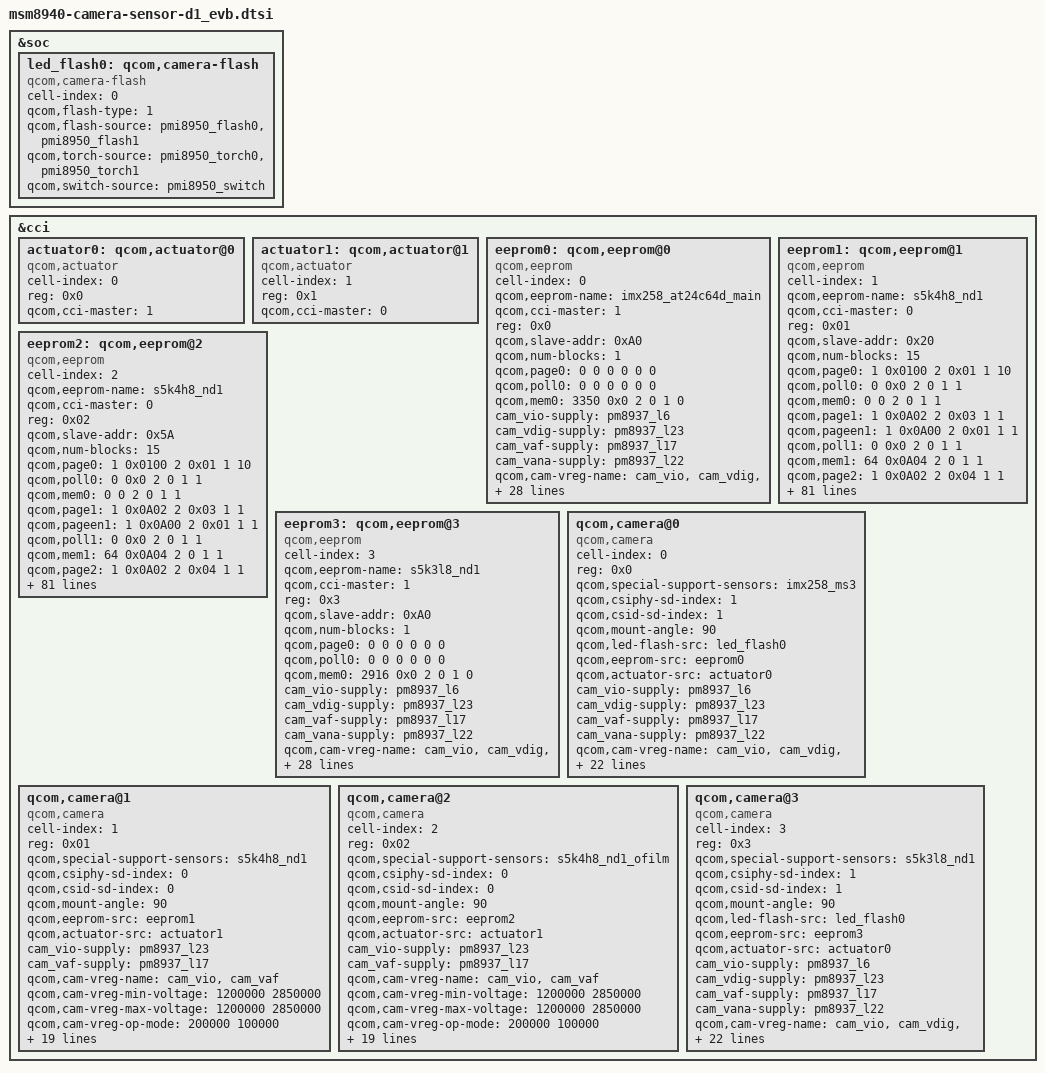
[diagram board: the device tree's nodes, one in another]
/*
 * Copyright (c) 2015-2016, The Linux Foundation. All rights reserved.
 *
 * This program is free software; you can redistribute it and/or modify
 * it under the terms of the GNU General Public License version 2 and
 * only version 2 as published by the Free Software Foundation.
 *
 * This program is distributed in the hope that it will be useful,
 * but WITHOUT ANY WARRANTY; without even the implied warranty of
 * MERCHANTABILITY or FITNESS FOR A PARTICULAR PURPOSE.  See the
 * GNU General Public License for more details.
 */
&soc {
	led_flash0: qcom,camera-flash {
		cell-index = <0>;
		compatible = "qcom,camera-flash";
		qcom,flash-type = <1>;
		qcom,flash-source = <&pmi8950_flash0 &pmi8950_flash1>;
		qcom,torch-source = <&pmi8950_torch0 &pmi8950_torch1>;
		qcom,switch-source = <&pmi8950_switch>;
	};
};

&cci {

  /delete-node/ qcom,actuator@1;
	/delete-node/ qcom,camera@2;

	actuator0: qcom,actuator@0 {
		cell-index = <0>;
		reg = <0x0>;
		compatible = "qcom,actuator";
		qcom,cci-master = <1>;
/*
		cam_vaf-supply = <&pm8937_l17>;
		qcom,cam-vreg-name = "cam_vaf";
		qcom,cam-vreg-min-voltage = <2850000>;
		qcom,cam-vreg-max-voltage = <2850000>;
		qcom,cam-vreg-op-mode = <80000>;
*/
	};

	actuator1: qcom,actuator@1 {
		cell-index = <1>;
		reg = <0x1>;
		compatible = "qcom,actuator";
		qcom,cci-master = <0>;
	};

	eeprom0: qcom,eeprom@0 {
		cell-index = <0>;
		qcom,eeprom-name = "imx258_at24c64d_main";
		compatible = "qcom,eeprom";
		qcom,cci-master = <1>;
		reg = <0x0>;
		qcom,slave-addr = <0xA0>;
		qcom,num-blocks = <1>;
		qcom,page0 = <0 0 0 0 0 0>;
		qcom,poll0 = <0 0 0 0 0 0>;
		qcom,mem0 = <3350 0x0 2 0 1 0>;
		cam_vio-supply = <&pm8937_l6>;
		cam_vdig-supply = <&pm8937_l23>;
		cam_vaf-supply = <&pm8937_l17>;
		cam_vana-supply = <&pm8937_l22>;
		qcom,cam-vreg-name = "cam_vio", "cam_vdig", "cam_vaf", "cam_vana";
		qcom,cam-vreg-min-voltage = <0 1200000 2850000 2800000>;
		qcom,cam-vreg-max-voltage = <0 1200000 2850000 2800000>;
		qcom,cam-vreg-op-mode = <0 200000 100000 80000>;
		pinctrl-names = "cam_default", "cam_suspend";
		pinctrl-0 = <&cam_sensor_mclk2_default
				&cam_sensor_rear_default>;
		pinctrl-1 = <&cam_sensor_mclk0_sleep &cam_sensor_rear_sleep>;
		gpios = <&tlmm 28 0>,
			<&tlmm 40 0>;
		qcom,gpio-reset = <1>;
		qcom,gpio-req-tbl-num = <0 1>;
		qcom,gpio-req-tbl-flags = <1 0>;
		qcom,gpio-req-tbl-label = "CAMIF_MCLK2",
			"CAM_RESET0";
		qcom,cam-power-seq-type = "sensor_gpio", "sensor_vreg", "sensor_vreg", "sensor_vreg",
			                      "sensor_gpio", "sensor_clk", "sensor_vreg";
		qcom,cam-power-seq-val = "sensor_gpio_reset", "cam_vdig", "cam_vana", "cam_vio",
			                     "sensor_gpio_reset", "sensor_cam_mclk", "cam_vaf";
		qcom,cam-power-seq-cfg-val = <0 0 0 0
		                              1 24000000 1>;
		qcom,cam-power-seq-delay = <0 0 0 0
		                            0 10 0>;
		status = "ok";
		clocks = <&clock_gcc clk_mclk2_clk_src>,
				<&clock_gcc clk_gcc_camss_mclk2_clk>;
		clock-names = "cam_src_clk", "cam_clk";
		qcom,clock-rates = <24000000 0>;
	};

	eeprom1: qcom,eeprom@1 {
		cell-index = <1>;
		qcom,eeprom-name = "s5k4h8_nd1";
		compatible = "qcom,eeprom";
		qcom,cci-master = <0>;
		reg = <0x01>;
		qcom,slave-addr = <0x20>;
		qcom,num-blocks = <15>;

		/*streaming on*/
		qcom,page0 = <1 0x0100 2 0x01 1 10>;
		qcom,poll0 = <0 0x0 2 0 1 1>;
		qcom,mem0 = <0 0 2 0 1 1>;

		/*set the PAGE3 of OTP*/
		/*read enable*/
		/*read 64byte buffer of page*/
		qcom,page1 = <1 0x0A02 2 0x03 1 1>;
		qcom,pageen1 = <1 0x0A00 2 0x01 1 1>;
		qcom,poll1 = <0 0x0 2 0 1 1>;
		qcom,mem1 = <64 0x0A04 2 0 1 1>;

		/*set the PAGE4 of OTP*/
		/*read enable*/
		/*read 64byte buffer of page*/
		qcom,page2 = <1 0x0A02 2 0x04 1 1>;
		qcom,pageen2 = <1 0x0A00 2 0x01 1 1>;
		qcom,poll2 = <0 0x0 2 0 1 1>;
		qcom,mem2 = <64 0x0A04 2 0 1 1>;

		/*set the PAGE5 of OTP*/
		/*read enable*/
		/*read 64byte buffer of page*/
		qcom,page3 = <1 0x0A02 2 0x05 1 1>;
		qcom,pageen3 = <1 0x0A00 2 0x01 1 1>;
		qcom,poll3 = <0 0x0 2 0 1 1>;
		qcom,mem3 = <64 0x0A04 2 0 1 1>;

		/*set the PAGE6 of OTP*/
		/*read enable*/
		/*read 64byte buffer of page*/
		qcom,page4 = <1 0x0A02 2 0x06 1 1>;
		qcom,pageen4 = <1 0x0A00 2 0x01 1 1>;
		qcom,poll4 = <0 0x0 2 0 1 1>;
		qcom,mem4 = <64 0x0A04 2 0 1 1>;

		/*set the PAGE7 of OTP*/
		/*read enable*/
		/*read 64byte buffer of page*/
		qcom,page5 = <1 0x0A02 2 0x07 1 1>;
		qcom,pageen5 = <1 0x0A00 2 0x01 1 1>;
		qcom,poll5 = <0 0x0 2 0 1 1>;
		qcom,mem5 = <64 0x0A04 2 0 1 1>;

		/*set the PAGE8 of OTP*/
		/*read enable*/
		/*read 64byte buffer of page*/
		qcom,page6 = <1 0x0A02 2 0x08 1 1>;
		qcom,pageen6 = <1 0x0A00 2 0x01 1 1>;
		qcom,poll6 = <0 0x0 2 0 1 1>;
		qcom,mem6 = <64 0x0A04 2 0 1 1>;

		/*set the PAGE9 of OTP*/
		/*read enable*/
		/*read 64byte buffer of page*/
		qcom,page7 = <1 0x0A02 2 0x09 1 1>;
		qcom,pageen7 = <1 0x0A00 2 0x01 1 1>;
		qcom,poll7 = <0 0x0 2 0 1 1>;
		qcom,mem7 = <64 0x0A04 2 0 1 1>;

		/*set the PAGE10 of OTP*/
		/*read enable*/
		/*read 64byte buffer of page*/
		qcom,page8 = <1 0x0A02 2 0x0A 1 1>;
		qcom,pageen8 = <1 0x0A00 2 0x01 1 1>;
		qcom,poll8 = <0 0x0 2 0 1 1>;
		qcom,mem8 = <64 0x0A04 2 0 1 1>;

		/*set the PAGE11 of OTP*/
		/*read enable*/
		/*read 64byte buffer of page*/
		qcom,page9 = <1 0x0A02 2 0x0B 1 1>;
		qcom,pageen9 = <1 0x0A00 2 0x01 1 1>;
		qcom,poll9 = <0 0x0 2 0 1 1>;
		qcom,mem9 = <64 0x0A04 2 0 1 1>;

		/*set the PAGE12 of OTP*/
		/*read enable*/
		/*read 64byte buffer of page*/
		qcom,page10 = <1 0x0A02 2 0x0C 1 1>;
		qcom,pageen10 = <1 0x0A00 2 0x01 1 1>;
		qcom,poll10 = <0 0x0 2 0 1 1>;
		qcom,mem10 = <64 0x0A04 2 0 1 1>;

		/*set the PAGE13 of OTP*/
		/*read enable*/
		/*read 64byte buffer of page*/
		qcom,page11 = <1 0x0A02 2 0x0D 1 1>;
		qcom,pageen11 = <1 0x0A00 2 0x01 1 1>;
		qcom,poll11 = <0 0x0 2 0 1 1>;
		qcom,mem11 = <64 0x0A04 2 0 1 1>;

		/*set the PAGE14 of OTP*/
		/*read enable*/
		/*read 64byte buffer of page*/
		qcom,page12 = <1 0x0A02 2 0x0E 1 1>;
		qcom,pageen12 = <1 0x0A00 2 0x01 1 1>;
		qcom,poll12 = <0 0x0 2 0 1 1>;
		qcom,mem12 = <64 0x0A04 2 0 1 1>;

		/*set the PAGE15 of OTP*/
		/*read enable*/
		/*read 64byte buffer of page*/
		qcom,page13 = <1 0x0A02 2 0x0F 1 1>;
		qcom,pageen13 = <1 0x0A00 2 0x01 1 1>;
		qcom,poll13 = <0 0x0 2 0 1 1>;
		qcom,mem13 = <64 0x0A04 2 0 1 1>;

		/*streaming off*/
		qcom,page14 = <1 0x0100 2 0x00 1 1>;
		qcom,poll14 = <0 0x0 2 0 1 1>;
		qcom,mem14 = <0 0 2 0 1 1>;

		cam_vio-supply = <&pm8937_l23>;
		qcom,cam-vreg-name = "cam_vio";
		qcom,cam-vreg-min-voltage = <1200000>;
		qcom,cam-vreg-max-voltage = <1200000>;
		qcom,cam-vreg-op-mode = <200000>;
		pinctrl-names = "cam_default", "cam_suspend";
		pinctrl-0 = <&cam_sensor_mclk0_default
				&cam_sensor_front1_default>;
		pinctrl-1 = <&cam_sensor_mclk0_sleep
				&cam_sensor_front1_sleep>;
		gpios = <&tlmm 26 0>,
			<&tlmm 36 0>,
			<&tlmm 8 0>,
			<&tlmm 9 0>;
		qcom,gpio-reset = <1>;
		qcom,gpio-vana = <2>;
		qcom,gpio-vdig = <3>;
		qcom,gpio-req-tbl-num = <0 1 2 3>;
		qcom,gpio-req-tbl-flags = <1 0 0 0>;
		qcom,gpio-req-tbl-label = "CAMIF_MCLK0",
			"CAM_RESET1",
			"CAM_2P8_EN",
			"CAM_1P2_EN";
		qcom,cam-power-seq-type = "sensor_gpio", "sensor_gpio", "sensor_gpio", "sensor_gpio",
		                                         "sensor_vreg", "sensor_gpio", "sensor_clk", "sensor_gpio";
		qcom,cam-power-seq-val = "sensor_gpio_vana", "sensor_gpio_vdig", "sensor_gpio_reset", "sensor_gpio_vana",
		                                      "cam_vio", "sensor_gpio_vdig", "sensor_cam_mclk", "sensor_gpio_reset";
		qcom,cam-power-seq-cfg-val = <0 0 0 1
		                              1 1 24000000 1>;
		qcom,cam-power-seq-delay = <0 0 0 0
		                            0 0 10 0>;
		status = "ok";
		clocks = <&clock_gcc clk_mclk0_clk_src>,
				<&clock_gcc clk_gcc_camss_mclk0_clk>;
		clock-names = "cam_src_clk", "cam_clk";
		qcom,clock-rates = <24000000 0>;
	};

	eeprom2: qcom,eeprom@2 {
		cell-index = <2>;
		qcom,eeprom-name = "s5k4h8_nd1";
		compatible = "qcom,eeprom";
		qcom,cci-master = <0>;
		reg = <0x02>;
		qcom,slave-addr = <0x5A>;
		qcom,num-blocks = <15>;

		/*streaming on*/
		qcom,page0 = <1 0x0100 2 0x01 1 10>;
		qcom,poll0 = <0 0x0 2 0 1 1>;
		qcom,mem0 = <0 0 2 0 1 1>;

		/*set the PAGE3 of OTP*/
		/*read enable*/
		/*read 64byte buffer of page*/
		qcom,page1 = <1 0x0A02 2 0x03 1 1>;
		qcom,pageen1 = <1 0x0A00 2 0x01 1 1>;
		qcom,poll1 = <0 0x0 2 0 1 1>;
		qcom,mem1 = <64 0x0A04 2 0 1 1>;

		/*set the PAGE4 of OTP*/
		/*read enable*/
		/*read 64byte buffer of page*/
		qcom,page2 = <1 0x0A02 2 0x04 1 1>;
		qcom,pageen2 = <1 0x0A00 2 0x01 1 1>;
		qcom,poll2 = <0 0x0 2 0 1 1>;
		qcom,mem2 = <64 0x0A04 2 0 1 1>;

		/*set the PAGE5 of OTP*/
		/*read enable*/
		/*read 64byte buffer of page*/
		qcom,page3 = <1 0x0A02 2 0x05 1 1>;
		qcom,pageen3 = <1 0x0A00 2 0x01 1 1>;
		qcom,poll3 = <0 0x0 2 0 1 1>;
		qcom,mem3 = <64 0x0A04 2 0 1 1>;

		/*set the PAGE6 of OTP*/
		/*read enable*/
		/*read 64byte buffer of page*/
		qcom,page4 = <1 0x0A02 2 0x06 1 1>;
		qcom,pageen4 = <1 0x0A00 2 0x01 1 1>;
		qcom,poll4 = <0 0x0 2 0 1 1>;
		qcom,mem4 = <64 0x0A04 2 0 1 1>;

		/*set the PAGE7 of OTP*/
		/*read enable*/
		/*read 64byte buffer of page*/
		qcom,page5 = <1 0x0A02 2 0x07 1 1>;
		qcom,pageen5 = <1 0x0A00 2 0x01 1 1>;
		qcom,poll5 = <0 0x0 2 0 1 1>;
		qcom,mem5 = <64 0x0A04 2 0 1 1>;

		/*set the PAGE8 of OTP*/
		/*read enable*/
		/*read 64byte buffer of page*/
		qcom,page6 = <1 0x0A02 2 0x08 1 1>;
		qcom,pageen6 = <1 0x0A00 2 0x01 1 1>;
		qcom,poll6 = <0 0x0 2 0 1 1>;
		qcom,mem6 = <64 0x0A04 2 0 1 1>;

		/*set the PAGE9 of OTP*/
		/*read enable*/
		/*read 64byte buffer of page*/
		qcom,page7 = <1 0x0A02 2 0x09 1 1>;
		qcom,pageen7 = <1 0x0A00 2 0x01 1 1>;
		qcom,poll7 = <0 0x0 2 0 1 1>;
		qcom,mem7 = <64 0x0A04 2 0 1 1>;

		/*set the PAGE10 of OTP*/
		/*read enable*/
		/*read 64byte buffer of page*/
		qcom,page8 = <1 0x0A02 2 0x0A 1 1>;
		qcom,pageen8 = <1 0x0A00 2 0x01 1 1>;
		qcom,poll8 = <0 0x0 2 0 1 1>;
		qcom,mem8 = <64 0x0A04 2 0 1 1>;

		/*set the PAGE11 of OTP*/
		/*read enable*/
		/*read 64byte buffer of page*/
		qcom,page9 = <1 0x0A02 2 0x0B 1 1>;
		qcom,pageen9 = <1 0x0A00 2 0x01 1 1>;
		qcom,poll9 = <0 0x0 2 0 1 1>;
		qcom,mem9 = <64 0x0A04 2 0 1 1>;

		/*set the PAGE12 of OTP*/
		/*read enable*/
		/*read 64byte buffer of page*/
		qcom,page10 = <1 0x0A02 2 0x0C 1 1>;
		qcom,pageen10 = <1 0x0A00 2 0x01 1 1>;
		qcom,poll10 = <0 0x0 2 0 1 1>;
		qcom,mem10 = <64 0x0A04 2 0 1 1>;

		/*set the PAGE13 of OTP*/
		/*read enable*/
		/*read 64byte buffer of page*/
		qcom,page11 = <1 0x0A02 2 0x0D 1 1>;
		qcom,pageen11 = <1 0x0A00 2 0x01 1 1>;
		qcom,poll11 = <0 0x0 2 0 1 1>;
		qcom,mem11 = <64 0x0A04 2 0 1 1>;

		/*set the PAGE14 of OTP*/
		/*read enable*/
		/*read 64byte buffer of page*/
		qcom,page12 = <1 0x0A02 2 0x0E 1 1>;
		qcom,pageen12 = <1 0x0A00 2 0x01 1 1>;
		qcom,poll12 = <0 0x0 2 0 1 1>;
		qcom,mem12 = <64 0x0A04 2 0 1 1>;

		/*set the PAGE15 of OTP*/
		/*read enable*/
		/*read 64byte buffer of page*/
		qcom,page13 = <1 0x0A02 2 0x0F 1 1>;
		qcom,pageen13 = <1 0x0A00 2 0x01 1 1>;
		qcom,poll13 = <0 0x0 2 0 1 1>;
		qcom,mem13 = <64 0x0A04 2 0 1 1>;

		/*streaming off*/
		qcom,page14 = <1 0x0100 2 0x00 1 1>;
		qcom,poll14 = <0 0x0 2 0 1 1>;
		qcom,mem14 = <0 0 2 0 1 1>;

		cam_vio-supply = <&pm8937_l23>;
		qcom,cam-vreg-name = "cam_vio";
		qcom,cam-vreg-min-voltage = <1200000>;
		qcom,cam-vreg-max-voltage = <1200000>;
		qcom,cam-vreg-op-mode = <200000>;
		pinctrl-names = "cam_default", "cam_suspend";
		pinctrl-0 = <&cam_sensor_mclk0_default
				&cam_sensor_front1_default>;
		pinctrl-1 = <&cam_sensor_mclk0_sleep
				&cam_sensor_front1_sleep>;
		gpios = <&tlmm 26 0>,
			<&tlmm 36 0>,
			<&tlmm 8 0>,
			<&tlmm 9 0>;
		qcom,gpio-reset = <1>;
		qcom,gpio-vana = <2>;
		qcom,gpio-vdig = <3>;
		qcom,gpio-req-tbl-num = <0 1 2 3>;
		qcom,gpio-req-tbl-flags = <1 0 0 0>;
		qcom,gpio-req-tbl-label = "CAMIF_MCLK0",
			"CAM_RESET1",
			"CAM_2P8_EN",
			"CAM_1P2_EN";
		qcom,cam-power-seq-type = "sensor_gpio", "sensor_gpio", "sensor_gpio", "sensor_gpio",
		                                         "sensor_vreg", "sensor_gpio", "sensor_clk", "sensor_gpio";
		qcom,cam-power-seq-val = "sensor_gpio_vana", "sensor_gpio_vdig", "sensor_gpio_reset", "sensor_gpio_vana",
		                                      "cam_vio", "sensor_gpio_vdig", "sensor_cam_mclk", "sensor_gpio_reset";
		qcom,cam-power-seq-cfg-val = <0 0 0 1
		                              1 1 24000000 1>;
		qcom,cam-power-seq-delay = <0 0 0 0
		                            0 0 10 0>;
		status = "ok";
		clocks = <&clock_gcc clk_mclk0_clk_src>,
				<&clock_gcc clk_gcc_camss_mclk0_clk>;
		clock-names = "cam_src_clk", "cam_clk";
		qcom,clock-rates = <24000000 0>;
	};

	eeprom3: qcom,eeprom@3 {
		cell-index = <3>;
		qcom,eeprom-name = "s5k3l8_nd1";
		compatible = "qcom,eeprom";
		qcom,cci-master = <1>;
		reg = <0x3>;
		qcom,slave-addr = <0xA0>;
		qcom,num-blocks = <1>;
		qcom,page0 = <0 0 0 0 0 0>;
		qcom,poll0 = <0 0 0 0 0 0>;
		qcom,mem0 = <2916 0x0 2 0 1 0>;
		cam_vio-supply = <&pm8937_l6>;
		cam_vdig-supply = <&pm8937_l23>;
		cam_vaf-supply = <&pm8937_l17>;
		cam_vana-supply = <&pm8937_l22>;
		qcom,cam-vreg-name = "cam_vio", "cam_vdig", "cam_vaf", "cam_vana";
		qcom,cam-vreg-min-voltage = <0 1200000 2850000 2800000>;
		qcom,cam-vreg-max-voltage = <0 1200000 2850000 2800000>;
		qcom,cam-vreg-op-mode = <0 200000 100000 80000>;
		pinctrl-names = "cam_default", "cam_suspend";
		pinctrl-0 = <&cam_sensor_mclk2_default
				&cam_sensor_rear_default>;
		pinctrl-1 = <&cam_sensor_mclk0_sleep &cam_sensor_rear_sleep>;
		gpios = <&tlmm 28 0>,
			<&tlmm 40 0>;
		qcom,gpio-reset = <1>;
		qcom,gpio-req-tbl-num = <0 1>;
		qcom,gpio-req-tbl-flags = <1 0>;
		qcom,gpio-req-tbl-label = "CAMIF_MCLK2",
			"CAM_RESET0";
		qcom,cam-power-seq-type = "sensor_gpio", "sensor_vreg", "sensor_vreg", "sensor_vreg",
			                      "sensor_gpio", "sensor_clk", "sensor_vreg";
		qcom,cam-power-seq-val = "sensor_gpio_reset", "cam_vdig", "cam_vana", "cam_vio",
			                     "sensor_gpio_reset", "sensor_cam_mclk", "cam_vaf";
		qcom,cam-power-seq-cfg-val = <0 0 0 0
		                              1 24000000 1>;
		qcom,cam-power-seq-delay = <0 0 0 0
		                            0 10 0>;
		status = "ok";
		clocks = <&clock_gcc clk_mclk2_clk_src>,
				<&clock_gcc clk_gcc_camss_mclk2_clk>;
		clock-names = "cam_src_clk", "cam_clk";
		qcom,clock-rates = <24000000 0>;
	};

	qcom,camera@0 {
		cell-index = <0>;
		compatible = "qcom,camera";
		reg = <0x0>;
		qcom,special-support-sensors = "imx258_ms3";
		qcom,csiphy-sd-index = <1>;
		qcom,csid-sd-index = <1>;
		qcom,mount-angle = <90>;
		qcom,led-flash-src = <&led_flash0>;
		qcom,eeprom-src = <&eeprom0>;
		qcom,actuator-src = <&actuator0>;
		cam_vio-supply = <&pm8937_l6>;
		cam_vdig-supply = <&pm8937_l23>;
		cam_vaf-supply = <&pm8937_l17>;
		cam_vana-supply = <&pm8937_l22>;
		qcom,cam-vreg-name = "cam_vio", "cam_vdig", "cam_vaf", "cam_vana";
		qcom,cam-vreg-min-voltage = <0 1200000 2850000 2800000>;
		qcom,cam-vreg-max-voltage = <0 1200000 2850000 2800000>;
		qcom,cam-vreg-op-mode = <0 200000 100000 80000>;
		pinctrl-names = "cam_default", "cam_suspend";
		pinctrl-0 = <&cam_sensor_mclk2_default
				&cam_sensor_rear_default>;
		pinctrl-1 = <&cam_sensor_mclk2_sleep &cam_sensor_rear_sleep>;
		gpios = <&tlmm 28 0>,
			<&tlmm 40 0>;
		qcom,gpio-reset = <1>;
		qcom,gpio-req-tbl-num = <0 1>;
		qcom,gpio-req-tbl-flags = <1 0>;
		qcom,gpio-req-tbl-label = "CAMIF_MCLK2",
			"CAM_RESET0";
		qcom,sensor-position = <0>;
		qcom,sensor-mode = <0>;
		qcom,cci-master = <1>;
		status = "ok";
		clocks = <&clock_gcc clk_mclk2_clk_src>,
				<&clock_gcc clk_gcc_camss_mclk2_clk>;
		clock-names = "cam_src_clk", "cam_clk";
		qcom,clock-rates = <24000000 0>;
	};

	qcom,camera@1 {
		cell-index = <1>;
		compatible = "qcom,camera";
		reg = <0x01>;
		qcom,special-support-sensors = "s5k4h8_nd1";
		qcom,csiphy-sd-index = <0>;
		qcom,csid-sd-index = <0>;
		qcom,mount-angle = <90>;
		qcom,eeprom-src = <&eeprom1>;
		qcom,actuator-src = <&actuator1>;
		cam_vio-supply = <&pm8937_l23>;
		cam_vaf-supply = <&pm8937_l17>;
		qcom,cam-vreg-name = "cam_vio", "cam_vaf";
		qcom,cam-vreg-min-voltage = <1200000 2850000>;
		qcom,cam-vreg-max-voltage = <1200000 2850000>;
		qcom,cam-vreg-op-mode = <200000 100000>;
		qcom,gpio-no-mux = <0>;
		pinctrl-names = "cam_default", "cam_suspend";
		pinctrl-0 = <&cam_sensor_mclk0_default
				&cam_sensor_front1_default>;
		pinctrl-1 = <&cam_sensor_mclk0_sleep
				&cam_sensor_front1_sleep>;
		gpios = <&tlmm 26 0>,
			<&tlmm 36 0>,
			<&tlmm 8 0>,
			<&tlmm 9 0>;
		qcom,gpio-reset = <1>;
		qcom,gpio-vana = <2>;
		qcom,gpio-vdig = <3>;
		qcom,gpio-req-tbl-num = <0 1 2 3>;
		qcom,gpio-req-tbl-flags = <1 0 0 0>;
		qcom,gpio-req-tbl-label = "CAMIF_MCLK0",
			"CAM_RESET1",
			"CAM_2P8_EN",
			"CAM_1P2_EN";
		qcom,sensor-position = <1>;
		qcom,sensor-mode = <0>;
		qcom,cci-master = <0>;
		status = "ok";
		clocks = <&clock_gcc clk_mclk0_clk_src>,
				<&clock_gcc clk_gcc_camss_mclk0_clk>;
		clock-names = "cam_src_clk", "cam_clk";
		qcom,clock-rates = <24000000 0>;
	};
	qcom,camera@2 {
		cell-index = <2>;
		compatible = "qcom,camera";
		reg = <0x02>;
		qcom,special-support-sensors = "s5k4h8_nd1_ofilm";
		qcom,csiphy-sd-index = <0>;
		qcom,csid-sd-index = <0>;
		qcom,mount-angle = <90>;
		qcom,eeprom-src = <&eeprom2>;
		qcom,actuator-src = <&actuator1>;
		cam_vio-supply = <&pm8937_l23>;
		cam_vaf-supply = <&pm8937_l17>;
		qcom,cam-vreg-name = "cam_vio", "cam_vaf";
		qcom,cam-vreg-min-voltage = <1200000 2850000>;
		qcom,cam-vreg-max-voltage = <1200000 2850000>;
		qcom,cam-vreg-op-mode = <200000 100000>;
		qcom,gpio-no-mux = <0>;
		pinctrl-names = "cam_default", "cam_suspend";
		pinctrl-0 = <&cam_sensor_mclk0_default
				&cam_sensor_front1_default>;
		pinctrl-1 = <&cam_sensor_mclk0_sleep
				&cam_sensor_front1_sleep>;
		gpios = <&tlmm 26 0>,
			<&tlmm 36 0>,
			<&tlmm 8 0>,
			<&tlmm 9 0>;
		qcom,gpio-reset = <1>;
		qcom,gpio-vana = <2>;
		qcom,gpio-vdig = <3>;
		qcom,gpio-req-tbl-num = <0 1 2 3>;
		qcom,gpio-req-tbl-flags = <1 0 0 0>;
		qcom,gpio-req-tbl-label = "CAMIF_MCLK0",
			"CAM_RESET1",
			"CAM_2P8_EN",
			"CAM_1P2_EN";
		qcom,sensor-position = <1>;
		qcom,sensor-mode = <0>;
		qcom,cci-master = <0>;
		status = "ok";
		clocks = <&clock_gcc clk_mclk0_clk_src>,
				<&clock_gcc clk_gcc_camss_mclk0_clk>;
		clock-names = "cam_src_clk", "cam_clk";
		qcom,clock-rates = <24000000 0>;
	};
	qcom,camera@3 {
		cell-index = <3>;
		compatible = "qcom,camera";
		reg = <0x3>;
		qcom,special-support-sensors = "s5k3l8_nd1";
		qcom,csiphy-sd-index = <1>;
		qcom,csid-sd-index = <1>;
		qcom,mount-angle = <90>;
		qcom,led-flash-src = <&led_flash0>;
		qcom,eeprom-src = <&eeprom3>;
		qcom,actuator-src = <&actuator0>;
		cam_vio-supply = <&pm8937_l6>;
		cam_vdig-supply = <&pm8937_l23>;
		cam_vaf-supply = <&pm8937_l17>;
		cam_vana-supply = <&pm8937_l22>;
		qcom,cam-vreg-name = "cam_vio", "cam_vdig", "cam_vaf", "cam_vana";
		qcom,cam-vreg-min-voltage = <0 1200000 2850000 2800000>;
		qcom,cam-vreg-max-voltage = <0 1200000 2850000 2800000>;
		qcom,cam-vreg-op-mode = <0 200000 100000 80000>;
		pinctrl-names = "cam_default", "cam_suspend";
		pinctrl-0 = <&cam_sensor_mclk2_default
				&cam_sensor_rear_default>;
		pinctrl-1 = <&cam_sensor_mclk2_sleep &cam_sensor_rear_sleep>;
		gpios = <&tlmm 28 0>,
			<&tlmm 40 0>;
		qcom,gpio-reset = <1>;
		qcom,gpio-req-tbl-num = <0 1>;
		qcom,gpio-req-tbl-flags = <1 0>;
		qcom,gpio-req-tbl-label = "CAMIF_MCLK2",
			"CAM_RESET0";
		qcom,sensor-position = <0>;
		qcom,sensor-mode = <0>;
		qcom,cci-master = <1>;
		status = "ok";
		clocks = <&clock_gcc clk_mclk2_clk_src>,
				<&clock_gcc clk_gcc_camss_mclk2_clk>;
		clock-names = "cam_src_clk", "cam_clk";
		qcom,clock-rates = <24000000 0>;
	};
};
